# SAM9X60 device description
Architecture: ARM926EJS; Family: SAM9; Series: SAM9X
Registers are 32-bit, read-write, no defined reset value unless marked. A register's access mark holds for its fields unless they carry their own. Offsets are from the block's base; [hi:lo] are bit positions; lines under a group give offsets from that group; {n}, {i} and the like mark numbered series; 'fields as' and 'values as' point back to an identical list.

## PMERRLOC — Programmable Multibit ECC Error Location
Instances: PMERRLOC 0xFFFFE600
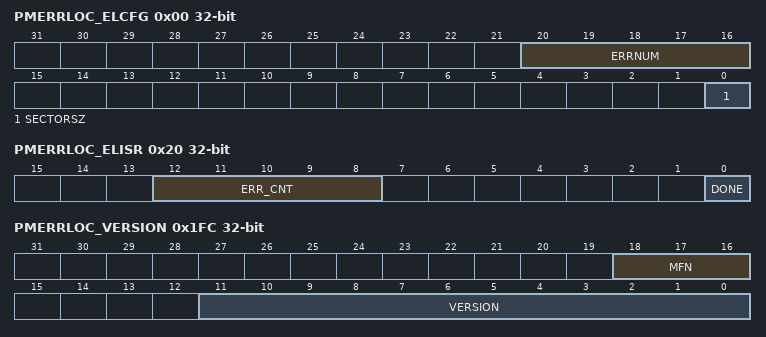
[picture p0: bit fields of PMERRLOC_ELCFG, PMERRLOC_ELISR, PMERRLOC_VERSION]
0x00 PMERRLOC_ELCFG — Configuration Register
  [20:16] ERRNUM — Number of Errors
  [0] SECTORSZ — Sector Size
0x04 PMERRLOC_ELPRIM ro — Primitive Register
  [15:0] PRIMITIV — Primitive Polynomial
0x08 PMERRLOC_ELEN — Enable Register
  [13:0] ENINIT — Initial Number of Bits in the Codeword
0x0C PMERRLOC_ELDIS — Disable Register
  [0] DIS — Disable Error Location Engine
0x10 PMERRLOC_ELSR — Status Register
  [0] BUSY — Error Location Engine Busy
0x14 PMERRLOC_ELIER wo — Interrupt Enable Register
  [0] DONE — Computation Terminated Interrupt Enable
0x18 PMERRLOC_ELIDR wo — Interrupt Disable Register
  [0] DONE — Computation Terminated Interrupt Disable
0x1C PMERRLOC_ELIMR ro — Interrupt Mask Register
  [0] DONE — Computation Terminated Interrupt Mask
0x20 PMERRLOC_ELISR ro — Interrupt Status Register
  [12:8] ERR_CNT — Error Counter Value
  [0] DONE — Computation Terminated Interrupt Status
0x28 PMERRLOC_SIGMA0 ro — SIGMA0 Register
  [13:0] SIGMA0 — Coefficient of Degree 0 in the SIGMA Polynomial
{0x28+4i} PMERRLOC_SIGMA{i} (i=1..23) — SIGMA1 Register
  [13:0] SIGMA{i} — Coefficient of Degree x in the SIGMA Polynomial.
0x88 PMERRLOC_SIGMA24 — SIGMA24 Register
  [13:0] SIGMA24 — Coefficient of Degree x in the SIGMA Polynomial.
{0x8C+4i} PMERRLOC_EL[{i}] (i=0..23) ro — Error Location 0 Register
  [13:0] ERRLOCN — Error Position within the Set {sector area, spare area}.
0x1FC PMERRLOC_VERSION ro — Version Register
  [18:16] MFN — Metal Fix Number
  [11:0] VERSION — Version of the Hardware Module

## PWM — Pulse Width Modulation Controller
Instances: PWM 0xF8034000
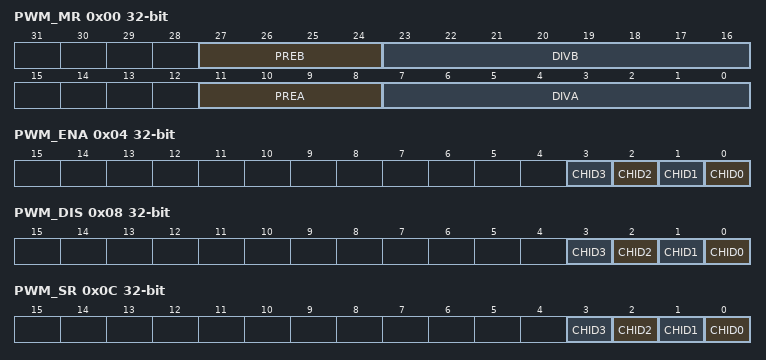
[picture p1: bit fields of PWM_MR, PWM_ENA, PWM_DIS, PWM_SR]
0x00 PWM_MR — PWM Mode Register
  [27:24] PREB — CLKB Source Clock Selection
    0=MCK (Master Clock); 1=MCKDIV2 (Master Clock divided by 2); 2=MCKDIV4 (Master Clock divided by 4); 3=MCKDIV8 (Master Clock divided by 8); 4=MCKDIV16 (Master Clock divided by 16); 5=MCKDIV32 (Master Clock divided by 32); 6=MCKDIV64 (Master Clock divided by 64); 7=MCKDIV128 (Master Clock divided by 128); 8=MCKDIV256 (Master Clock divided by 256); 9=MCKDIV512 (Master Clock divided by 512); 10=MCKDIV1024 (Master Clock divided by 1024)
  [23:16] DIVB — CLKB Divide Factor
    0=CLK_OFF (CLKB clock is turned off); 1=CLK_DIV1 (CLKB clock is clock selected by PREB)
  [11:8] PREA — CLKA Source Clock Selection
    values as PREB
  [7:0] DIVA — CLKA Divide Factor
    0=CLK_OFF (CLKA clock is turned off); 1=CLK_DIV1 (CLKA clock is clock selected by PREA)
0x04 PWM_ENA wo — PWM Enable Register
  [n] CHID{n} (n=0..3) — Channel ID
0x08 PWM_DIS wo — PWM Disable Register
  [n] CHID{n} (n=0..3) — Channel ID
0x0C PWM_SR ro — PWM Status Register
  [n] CHID{n} (n=0..3) — Channel ID
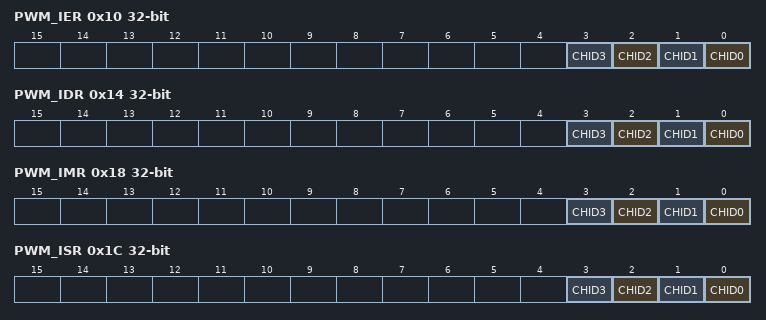
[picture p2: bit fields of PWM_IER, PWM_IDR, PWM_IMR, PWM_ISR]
0x10 PWM_IER wo — PWM Interrupt Enable Register
  [n] CHID{n} (n=0..3) — Channel ID
0x14 PWM_IDR wo — PWM Interrupt Disable Register
  [n] CHID{n} (n=0..3) — Channel ID
0x18 PWM_IMR ro — PWM Interrupt Mask Register
  [n] CHID{n} (n=0..3) — Channel ID
0x1C PWM_ISR ro — PWM Interrupt Status Register
  [n] CHID{n} (n=0..3) — Channel ID
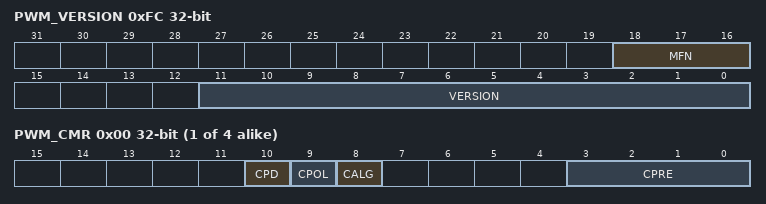
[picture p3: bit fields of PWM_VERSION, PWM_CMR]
0xFC PWM_VERSION ro — Version Register
  [18:16] MFN — Metal Fix Number
  [11:0] VERSION — Version of the Hardware Module
{0x200+0x20*i} PWM_CH_NUM[{i}] (i=0..3) group
  0x00 PWM_CMR — PWM Channel Mode Register
    [10] CPD — Channel Update Period
    [9] CPOL — Channel Polarity
      0=LOW_POLARITY (Waveform starts at low level); 1=HIGH_POLARITY (Waveform starts at high level)
    [8] CALG — Channel Alignment
      0=LEFT_ALIGNED; 1=CENTER_ALIGNED
    [3:0] CPRE — Channel Prescaler
      0=MCK (Master Clock); 1=MCKDIV2 (Master Clock divided by 2); 2=MCKDIV4 (Master Clock divided by 4); 3=MCKDIV8 (Master Clock divided by 8); 4=MCKDIV16 (Master Clock divided by 16); 5=MCKDIV32 (Master Clock divided by 32); 6=MCKDIV64 (Master Clock divided by 64); 7=MCKDIV128 (Master Clock divided by 128); 8=MCKDIV256 (Master Clock divided by 256); 9=MCKDIV512 (Master Clock divided by 512); 10=MCKDIV1024 (Master Clock divided by 1024); 11=CLKA (Clock A); 12=CLKB (Clock B)
  0x04 PWM_CDTY — PWM Channel Duty Cycle Register
    [31:0] CDTY — Channel Duty Cycle
  0x08 PWM_CPRD — PWM Channel Period Register
    [31:0] CPRD — Channel Period
  0x0C PWM_CCNT ro — PWM Channel Counter Register
    [31:0] CNT — Channel Counter Register
  0x10 PWM_CUPD wo — PWM Channel Update Register
    [31:0] CUPD — Channel Update Register
